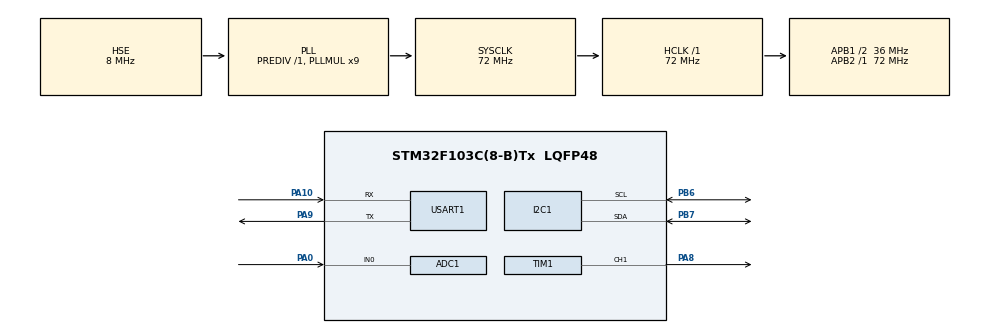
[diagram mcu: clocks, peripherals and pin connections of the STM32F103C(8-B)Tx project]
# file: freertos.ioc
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ADC1.Channel-0\#ChannelRegularConversion=ADC_CHANNEL_0
ADC1.NbrOfConversionFlag=1
ADC1.Rank-0\#ChannelRegularConversion=1
ADC1.SamplingTime-0\#ChannelRegularConversion=ADC_SAMPLETIME_1CYCLE_5
ADC1.master=1
FREERTOS.BinarySemaphores01=SerialSemaphore,Dynamic,NULL,Depleted
FREERTOS.Queues01=Queue01,2,uint16_t,0,Dynamic,NULL,NULL;Queue02,2,uint16_t,0,Dynamic,NULL,NULL
FREERTOS.Tasks01=ADCTask,40,128,StartADCTask,As weak,NULL,Dynamic,NULL,NULL;ServoTask,40,128,StartServoTask,As weak,NULL,Dynamic,NULL,NULL;SerialTask,24,1024,StartSerialTask,As weak,NULL,Dynamic,NULL,NULL;OLEDTask,40,512,StartOLEDTask,As weak,NULL,Dynamic,NULL,NULL
FREERTOS.configTOTAL_HEAP_SIZE=10000
I2C1.I2C_Mode=I2C_Fast
Mcu.Family=STM32F1
Mcu.Name=STM32F103C(8-B)Tx
Mcu.Package=LQFP48
NVIC.PriorityGroup=NVIC_PRIORITYGROUP_4
NVIC.TIM2_IRQn=true\:15\:0\:false\:false\:true\:false\:false\:true\:true
NVIC.TimeBase=TIM2_IRQn
NVIC.TimeBaseIP=TIM2
NVIC.USART1_IRQn=true\:5\:0\:false\:false\:true\:true\:true\:true\:true
PA0-WKUP.Signal=ADCx_IN0
PA10.Mode=Asynchronous
PA10.Signal=USART1_RX
PA13.Mode=Serial_Wire
PA13.Signal=SYS_JTMS-SWDIO
PA14.Mode=Serial_Wire
PA14.Signal=SYS_JTCK-SWCLK
PA8.Signal=S_TIM1_CH1
PA9.Mode=Asynchronous
PA9.Signal=USART1_TX
PB6.Mode=I2C
PB6.Signal=I2C1_SCL
PB7.Mode=I2C
PB7.Signal=I2C1_SDA
PD0-OSC_IN.Mode=HSE-External-Oscillator
PD0-OSC_IN.Signal=RCC_OSC_IN
PD1-OSC_OUT.Mode=HSE-External-Oscillator
PD1-OSC_OUT.Signal=RCC_OSC_OUT
ProjectManager.HeapSize=0x200
ProjectManager.StackSize=0x400
ProjectManager.TargetToolchain=MDK-ARM V5.32
RCC.ADCPresc=RCC_ADCPCLK2_DIV6
RCC.AHBFreq_Value=72000000
RCC.APB1CLKDivider=RCC_HCLK_DIV2
RCC.APB1Freq_Value=36000000
RCC.APB1TimFreq_Value=72000000
RCC.APB2Freq_Value=72000000
RCC.APB2TimFreq_Value=72000000
RCC.HCLKFreq_Value=72000000
RCC.PLLMUL=RCC_PLL_MUL9
RCC.PLLSourceVirtual=RCC_PLLSOURCE_HSE
RCC.SYSCLKFreq_VALUE=72000000
RCC.SYSCLKSource=RCC_SYSCLKSOURCE_PLLCLK
RCC.USBFreq_Value=72000000
SH.ADCx_IN0.0=ADC1_IN0,IN0
SH.S_TIM1_CH1.0=TIM1_CH1,PWM Generation1 CH1
TIM1.Channel-PWM\ Generation1\ CH1=TIM_CHANNEL_1
TIM1.Period=1999
TIM1.Prescaler=719
USART1.VirtualMode=VM_ASYNC
VP_FREERTOS_VS_CMSIS_V2.Mode=CMSIS_V2
VP_SYS_VS_tim2.Mode=TIM2
board=custom

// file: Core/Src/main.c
/* USER CODE BEGIN Header */
/**
  ******************************************************************************
  * @file           : main.c
  * @brief          : Main program body
  ******************************************************************************
  * @attention
  *
  * Copyright (c) 2026 STMicroelectronics.
  * All rights reserved.
  *
  * This software is licensed under terms that can be found in the LICENSE file
  * in the root directory of this software component.
  * If no LICENSE file comes with this software, it is provided AS-IS.
  *
  ******************************************************************************
  */
/* USER CODE END Header */
#include "main.h"
#include "cmsis_os.h"
#include "adc.h"
#include "i2c.h"
#include "tim.h"
#include "usart.h"
#include "gpio.h"

/* USER CODE BEGIN Includes */
#include "brv_i2c_oled.h"
/* USER CODE END Includes */

/* USER CODE BEGIN PV */
volatile ControlMode CurrentMode=MODE_LIGHT;
/* USER CODE END PV */

void SystemClock_Config(void);
void MX_FREERTOS_Init(void);

int main(void)
{

  /* MCU Configuration--------------------------------------------------------*/

  /* Reset of all peripherals, Initializes the Flash interface and the Systick. */
  HAL_Init();

  /* Configure the system clock */
  SystemClock_Config();

  /* Initialize all configured peripherals */
  MX_GPIO_Init();
  MX_USART1_UART_Init();
  MX_ADC1_Init();
  MX_TIM1_Init();
  MX_I2C1_Init();
  /* USER CODE BEGIN 2 */
	OLED_Init();//ʹ��OLED
  /* USER CODE END 2 */

  /* Init scheduler */
  osKernelInitialize();  /* Call init function for freertos objects (in cmsis_os2.c) */
  MX_FREERTOS_Init();

  /* Start scheduler */
  osKernelStart();

  /* We should never get here as control is now taken by the scheduler */

  /* Infinite loop */
  while (1)
  {

  }
}

void SystemClock_Config(void)
{
  RCC_OscInitTypeDef RCC_OscInitStruct = {0};
  RCC_ClkInitTypeDef RCC_ClkInitStruct = {0};
  RCC_PeriphCLKInitTypeDef PeriphClkInit = {0};

  /** Initializes the RCC Oscillators according to the specified parameters
  * in the RCC_OscInitTypeDef structure.
  */
  RCC_OscInitStruct.OscillatorType = RCC_OSCILLATORTYPE_HSE;
  RCC_OscInitStruct.HSEState = RCC_HSE_ON;
  RCC_OscInitStruct.HSEPredivValue = RCC_HSE_PREDIV_DIV1;
  RCC_OscInitStruct.HSIState = RCC_HSI_ON;
  RCC_OscInitStruct.PLL.PLLState = RCC_PLL_ON;
  RCC_OscInitStruct.PLL.PLLSource = RCC_PLLSOURCE_HSE;
  RCC_OscInitStruct.PLL.PLLMUL = RCC_PLL_MUL9;
  if (HAL_RCC_OscConfig(&RCC_OscInitStruct) != HAL_OK)
  {
    Error_Handler();
  }

  /** Initializes the CPU, AHB and APB buses clocks
  */
  RCC_ClkInitStruct.ClockType = RCC_CLOCKTYPE_HCLK|RCC_CLOCKTYPE_SYSCLK
                              |RCC_CLOCKTYPE_PCLK1|RCC_CLOCKTYPE_PCLK2;
  RCC_ClkInitStruct.SYSCLKSource = RCC_SYSCLKSOURCE_PLLCLK;
  RCC_ClkInitStruct.AHBCLKDivider = RCC_SYSCLK_DIV1;
  RCC_ClkInitStruct.APB1CLKDivider = RCC_HCLK_DIV2;
  RCC_ClkInitStruct.APB2CLKDivider = RCC_HCLK_DIV1;

  if (HAL_RCC_ClockConfig(&RCC_ClkInitStruct, FLASH_LATENCY_2) != HAL_OK)
  {
    Error_Handler();
  }
  PeriphClkInit.PeriphClockSelection = RCC_PERIPHCLK_ADC;
  PeriphClkInit.AdcClockSelection = RCC_ADCPCLK2_DIV6;
  if (HAL_RCCEx_PeriphCLKConfig(&PeriphClkInit) != HAL_OK)
  {
    Error_Handler();
  }
}

void HAL_TIM_PeriodElapsedCallback(TIM_HandleTypeDef *htim)
{
  if (htim->Instance == TIM2)
  {
    HAL_IncTick();
  }
}

void Error_Handler(void)
{
  __disable_irq();
  while (1)
  {
  }
}

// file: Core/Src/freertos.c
/* USER CODE BEGIN Header */
/**
  ******************************************************************************
  * File Name          : freertos.c
  * Description        : Code for freertos applications
  ******************************************************************************
  * @attention
  *
  * Copyright (c) 2026 STMicroelectronics.
  * All rights reserved.
  *
  * This software is licensed under terms that can be found in the LICENSE file
  * in the root directory of this software component.
  * If no LICENSE file comes with this software, it is provided AS-IS.
  *
  ******************************************************************************
  */
/* USER CODE END Header */

#include "FreeRTOS.h"
#include "task.h"
#include "main.h"
#include "cmsis_os.h"

/* Definitions for ADCTask */
osThreadId_t ADCTaskHandle;
const osThreadAttr_t ADCTask_attributes = {
  .name = "ADCTask",
  .stack_size = 128 * 4,
  .priority = (osPriority_t) osPriorityHigh,
};
/* Definitions for ServoTask */
osThreadId_t ServoTaskHandle;
const osThreadAttr_t ServoTask_attributes = {
  .name = "ServoTask",
  .stack_size = 128 * 4,
  .priority = (osPriority_t) osPriorityHigh,
};
/* Definitions for SerialTask */
osThreadId_t SerialTaskHandle;
const osThreadAttr_t SerialTask_attributes = {
  .name = "SerialTask",
  .stack_size = 1024 * 4,
  .priority = (osPriority_t) osPriorityNormal,
};
/* Definitions for OLEDTask */
osThreadId_t OLEDTaskHandle;
const osThreadAttr_t OLEDTask_attributes = {
  .name = "OLEDTask",
  .stack_size = 512 * 4,
  .priority = (osPriority_t) osPriorityHigh,
};
/* Definitions for Queue01 */
osMessageQueueId_t Queue01Handle;
const osMessageQueueAttr_t Queue01_attributes = {
  .name = "Queue01"
};
/* Definitions for Queue02 */
osMessageQueueId_t Queue02Handle;
const osMessageQueueAttr_t Queue02_attributes = {
  .name = "Queue02"
};
/* Definitions for SerialSemaphore */
osSemaphoreId_t SerialSemaphoreHandle;
const osSemaphoreAttr_t SerialSemaphore_attributes = {
  .name = "SerialSemaphore"
};

void StartADCTask(void *argument);
void StartServoTask(void *argument);
void StartSerialTask(void *argument);
void StartOLEDTask(void *argument);

void MX_FREERTOS_Init(void); /* (MISRA C 2004 rule 8.1) */

void MX_FREERTOS_Init(void) {

  /* Create the semaphores(s) */
  /* creation of SerialSemaphore */
  SerialSemaphoreHandle = osSemaphoreNew(1, 0, &SerialSemaphore_attributes);

  /* Create the queue(s) */
  /* creation of Queue01 */
  Queue01Handle = osMessageQueueNew (2, sizeof(uint16_t), &Queue01_attributes);

  /* creation of Queue02 */
  Queue02Handle = osMessageQueueNew (2, sizeof(uint16_t), &Queue02_attributes);

  /* Create the thread(s) */
  /* creation of ADCTask */
  ADCTaskHandle = osThreadNew(StartADCTask, NULL, &ADCTask_attributes);

  /* creation of ServoTask */
  ServoTaskHandle = osThreadNew(StartServoTask, NULL, &ServoTask_attributes);

  /* creation of SerialTask */
  SerialTaskHandle = osThreadNew(StartSerialTask, NULL, &SerialTask_attributes);

  /* creation of OLEDTask */
  OLEDTaskHandle = osThreadNew(StartOLEDTask, NULL, &OLEDTask_attributes);

}

__weak void StartADCTask(void *argument)
{
  for(;;)
  {
    osDelay(1);
  }
}

__weak void StartServoTask(void *argument)
{
  for(;;)
  {
    osDelay(1);
  }
}

__weak void StartSerialTask(void *argument)
{
  for(;;)
  {
    osDelay(1);
  }
}

__weak void StartOLEDTask(void *argument)
{
  for(;;)
  {
    osDelay(1);
  }
}
